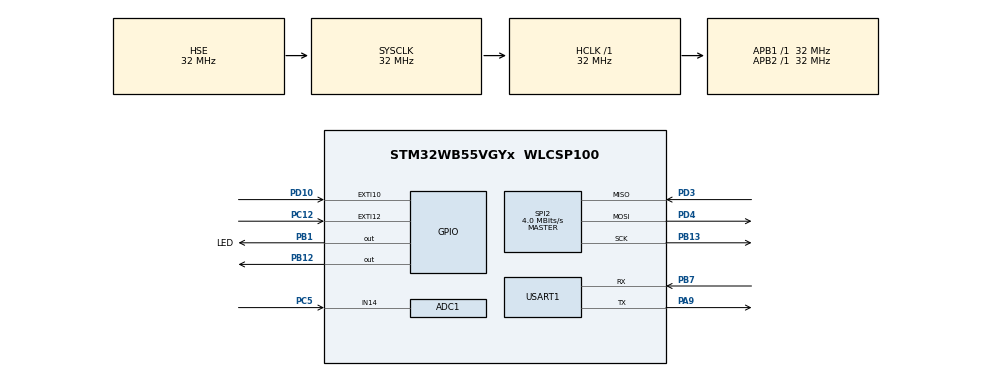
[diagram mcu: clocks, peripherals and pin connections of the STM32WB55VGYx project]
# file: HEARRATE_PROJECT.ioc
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ADC1.Channel-0\#ChannelRegularConversion=ADC_CHANNEL_14
ADC1.NbrOfConversionFlag=1
ADC1.OffsetNumber-0\#ChannelRegularConversion=ADC_OFFSET_NONE
ADC1.Rank-0\#ChannelRegularConversion=1
ADC1.SamplingTime-0\#ChannelRegularConversion=ADC_SAMPLETIME_2CYCLES_5
ADC1.master=1
Dma.Request0=USART1_RX
Dma.Request1=USART1_TX
Dma.Request2=SPI2_RX
Dma.Request3=SPI2_TX
Dma.SPI2_RX.2.Direction=DMA_PERIPH_TO_MEMORY
Dma.SPI2_RX.2.EventEnable=DISABLE
Dma.SPI2_RX.2.Instance=DMA1_Channel3
Dma.SPI2_RX.2.MemDataAlignment=DMA_MDATAALIGN_BYTE
Dma.SPI2_RX.2.MemInc=DMA_MINC_ENABLE
Dma.SPI2_RX.2.Mode=DMA_NORMAL
Dma.SPI2_RX.2.PeriphDataAlignment=DMA_PDATAALIGN_BYTE
Dma.SPI2_RX.2.PeriphInc=DMA_PINC_DISABLE
Dma.SPI2_RX.2.Polarity=HAL_DMAMUX_REQ_GEN_RISING
Dma.SPI2_RX.2.Priority=DMA_PRIORITY_LOW
Dma.SPI2_RX.2.RequestNumber=1
Dma.SPI2_RX.2.SignalID=NONE
Dma.SPI2_RX.2.SyncEnable=DISABLE
Dma.SPI2_RX.2.SyncPolarity=HAL_DMAMUX_SYNC_NO_EVENT
Dma.SPI2_RX.2.SyncRequestNumber=1
Dma.SPI2_RX.2.SyncSignalID=NONE
Dma.SPI2_TX.3.Direction=DMA_MEMORY_TO_PERIPH
Dma.SPI2_TX.3.EventEnable=DISABLE
Dma.SPI2_TX.3.Instance=DMA1_Channel4
Dma.SPI2_TX.3.MemDataAlignment=DMA_MDATAALIGN_BYTE
Dma.SPI2_TX.3.MemInc=DMA_MINC_ENABLE
Dma.SPI2_TX.3.Mode=DMA_NORMAL
Dma.SPI2_TX.3.PeriphDataAlignment=DMA_PDATAALIGN_BYTE
Dma.SPI2_TX.3.PeriphInc=DMA_PINC_DISABLE
Dma.SPI2_TX.3.Polarity=HAL_DMAMUX_REQ_GEN_RISING
Dma.SPI2_TX.3.Priority=DMA_PRIORITY_LOW
Dma.SPI2_TX.3.RequestNumber=1
Dma.SPI2_TX.3.SignalID=NONE
Dma.SPI2_TX.3.SyncEnable=DISABLE
Dma.SPI2_TX.3.SyncPolarity=HAL_DMAMUX_SYNC_NO_EVENT
Dma.SPI2_TX.3.SyncRequestNumber=1
Dma.SPI2_TX.3.SyncSignalID=NONE
Dma.USART1_RX.0.Direction=DMA_PERIPH_TO_MEMORY
Dma.USART1_RX.0.EventEnable=DISABLE
Dma.USART1_RX.0.Instance=DMA1_Channel1
Dma.USART1_RX.0.MemDataAlignment=DMA_MDATAALIGN_BYTE
Dma.USART1_RX.0.MemInc=DMA_MINC_ENABLE
Dma.USART1_RX.0.Mode=DMA_NORMAL
Dma.USART1_RX.0.PeriphDataAlignment=DMA_PDATAALIGN_BYTE
Dma.USART1_RX.0.PeriphInc=DMA_PINC_DISABLE
Dma.USART1_RX.0.Polarity=HAL_DMAMUX_REQ_GEN_RISING
Dma.USART1_RX.0.Priority=DMA_PRIORITY_LOW
Dma.USART1_RX.0.RequestNumber=1
Dma.USART1_RX.0.SignalID=NONE
Dma.USART1_RX.0.SyncEnable=DISABLE
Dma.USART1_RX.0.SyncPolarity=HAL_DMAMUX_SYNC_NO_EVENT
Dma.USART1_RX.0.SyncRequestNumber=1
Dma.USART1_RX.0.SyncSignalID=NONE
Dma.USART1_TX.1.Direction=DMA_MEMORY_TO_PERIPH
Dma.USART1_TX.1.EventEnable=DISABLE
Dma.USART1_TX.1.Instance=DMA1_Channel2
Dma.USART1_TX.1.MemDataAlignment=DMA_MDATAALIGN_BYTE
Dma.USART1_TX.1.MemInc=DMA_MINC_ENABLE
Dma.USART1_TX.1.Mode=DMA_NORMAL
Dma.USART1_TX.1.PeriphDataAlignment=DMA_PDATAALIGN_BYTE
Dma.USART1_TX.1.PeriphInc=DMA_PINC_DISABLE
Dma.USART1_TX.1.Polarity=HAL_DMAMUX_REQ_GEN_RISING
Dma.USART1_TX.1.Priority=DMA_PRIORITY_LOW
Dma.USART1_TX.1.RequestNumber=1
Dma.USART1_TX.1.SignalID=NONE
Dma.USART1_TX.1.SyncEnable=DISABLE
Dma.USART1_TX.1.SyncPolarity=HAL_DMAMUX_SYNC_NO_EVENT
Dma.USART1_TX.1.SyncRequestNumber=1
Dma.USART1_TX.1.SyncSignalID=NONE
Mcu.Family=STM32WB
Mcu.Name=STM32WB55VGYx
Mcu.Package=WLCSP100
NVIC.DMA1_Channel1_IRQn=true\:0\:0\:false\:false\:true\:false\:true\:true
NVIC.DMA1_Channel2_IRQn=true\:0\:0\:false\:false\:true\:false\:true\:true
NVIC.DMA1_Channel3_IRQn=true\:0\:0\:false\:false\:true\:false\:true\:true
NVIC.DMA1_Channel4_IRQn=true\:0\:0\:false\:false\:true\:false\:true\:true
NVIC.HSEM_IRQn=true\:0\:0\:false\:false\:true\:false\:true\:true
NVIC.PriorityGroup=NVIC_PRIORITYGROUP_4
NVIC.RTC_WKUP_IRQn=true\:0\:0\:false\:false\:true\:true\:true\:true
NVIC.SPI2_IRQn=true\:0\:0\:false\:false\:true\:true\:true\:true
NVIC.USART1_IRQn=true\:0\:0\:false\:false\:true\:true\:true\:true
OSC_IN.Mode=HSE-External-Oscillator
OSC_IN.Signal=RCC_OSC_IN
OSC_OUT.Mode=HSE-External-Oscillator
OSC_OUT.Signal=RCC_OSC_OUT
PA13.Mode=Serial_Wire
PA13.Signal=SYS_JTMS-SWDIO
PA14.Mode=Serial_Wire
PA14.Signal=SYS_JTCK-SWCLK
PA9.Mode=Asynchronous
PA9.Signal=USART1_TX
PB1.GPIO_Label=LED
PB1.Signal=GPIO_Output
PB12.Signal=GPIO_Output
PB13.Mode=Full_Duplex_Master
PB13.Signal=SPI2_SCK
PB7.Mode=Asynchronous
PB7.Signal=USART1_RX
PC12.Signal=GPXTI12
PC14-OSC32_IN.Mode=LSE-External-Oscillator
PC14-OSC32_IN.Signal=RCC_OSC32_IN
PC15-OSC32_OUT.Mode=LSE-External-Oscillator
PC15-OSC32_OUT.Signal=RCC_OSC32_OUT
PC5.Signal=ADCx_IN14
PD10.Signal=GPXTI10
PD3.Mode=Full_Duplex_Master
PD3.Signal=SPI2_MISO
PD4.Mode=Full_Duplex_Master
PD4.Signal=SPI2_MOSI
ProjectManager.HeapSize=0x200
ProjectManager.StackSize=0x400
ProjectManager.TargetToolchain=STM32CubeIDE
RCC.AHBFreq_Value=32000000
RCC.APB1Freq_Value=32000000
RCC.APB1TimFreq_Value=32000000
RCC.APB2Freq_Value=32000000
RCC.APB2TimFreq_Value=32000000
RCC.APB3Freq_Value=16000000
RCC.CortexFreq_Value=32000000
RCC.HCLKFreq_Value=32000000
RCC.HSE_VALUE=32000000
RCC.HSI48_VALUE=48000000
RCC.HSI_VALUE=16000000
RCC.RFWKPClockSelection=RCC_RFWKPCLKSOURCE_LSE
RCC.RTCClockSelection=RCC_RTCCLKSOURCE_LSE
RCC.SMPSCLockSelection=RCC_SMPSCLKSOURCE_HSE
RCC.SYSCLKFreq_VALUE=32000000
RCC.SYSCLKSource=RCC_SYSCLKSOURCE_HSE
RCC.VCOOutputFreq_Value=32000000
RF1.Mode=RF1_Activate
RF1.Signal=RF_RF1
SH.ADCx_IN14.0=ADC1_IN14,IN14-Single-Ended
SPI2.BaudRatePrescaler=SPI_BAUDRATEPRESCALER_8
SPI2.CLKPhase=SPI_PHASE_1EDGE
SPI2.CalculateBaudRate=4.0 MBits/s
SPI2.DataSize=SPI_DATASIZE_8BIT
SPI2.Direction=SPI_DIRECTION_2LINES
SPI2.Mode=SPI_MODE_MASTER
SPI2.VirtualType=VM_MASTER
STM32_WPAN.BLE_DBG_APP_EN=1
STM32_WPAN.BT_SIG_HEART_RATE_SENSOR=Disabled
STM32_WPAN.CFG_DEBUGGER_SUPPORTED=1
STM32_WPAN.CFG_DEBUG_APP_TRACE=1
STM32_WPAN.CFG_DEBUG_BLE_TRACE=1
STM32_WPAN.CFG_DEBUG_TRACE_FULL=1
STM32_WPAN.CFG_DEBUG_TRACE_LIGHT=0
STM32_WPAN.CFG_DEBUG_TRACE_UART=hw_uart1
STM32_WPAN.CFG_HW_USART1_ENABLED=1
STM32_WPAN.CFG_LPM_SUPPORTED=1
STM32_WPAN.CFG_LSCLK_LSE=0
STM32_WPAN.CFG_USE_SMPS=1
STM32_WPAN.CUSTOM_P2P_SERVER=Disabled
STM32_WPAN.CUSTOM_TEMPLATE=Enabled
STM32_WPAN.INCLUDE_AD_TYPE_COMPLETE_LOCAL_NAME=0
STM32_WPAN.INCLUDE_AD_TYPE_TX_POWER_LEVEL=1
STM32_WPAN.LOCAL_NAME=HEART
STM32_WPAN.LOCAL_NAME_FORMATTED=,'H','E','A','R','T'
STM32_WPAN.NUMBER_OF_SERVICES=1
STM32_WPAN.SERVICE1_CHAR1_ATTR_PERMISSION_AUTHEN_READ=\ 
STM32_WPAN.SERVICE1_CHAR1_ATTR_PERMISSION_AUTHEN_WRITE=\ 
STM32_WPAN.SERVICE1_CHAR1_ATTR_PERMISSION_AUTHOR_READ=\ 
STM32_WPAN.SERVICE1_CHAR1_ATTR_PERMISSION_AUTHOR_WRITE=\ 
STM32_WPAN.SERVICE1_CHAR1_GATT_NOTIFY_ATTRIBUTE_WRITE=\ 
STM32_WPAN.SERVICE1_CHAR1_GATT_NOTIFY_READ_REQ_AND_WAIT_FOR_APPL_RESP=\ 
STM32_WPAN.SERVICE1_CHAR1_GATT_NOTIFY_WRITE_REQ_AND_WAIT_FOR_APPL_RESP=\ 
STM32_WPAN.SERVICE1_CHAR1_LONG_NAME=DATA_SEND
STM32_WPAN.SERVICE1_CHAR1_PROP_NOTIFY=CHAR_PROP_NOTIFY
STM32_WPAN.SERVICE1_CHAR1_SHORT_NAME=DATA_SEND
STM32_WPAN.SERVICE1_LONG_NAME=PEDOMETER
STM32_WPAN.SERVICE1_SHORT_NAME=PEDOMETER
USART1.FIFOMode=FIFOMODE_DISABLE
USART1.VirtualMode-Asynchronous=VM_ASYNC
VP_HSEM_VS_HSEM.Mode=HSEM_Activate
VP_IPCC_VS_IPCC.Mode=IPCC_Activate
VP_MEMORYMAP_VS_MEMORYMAP.Mode=CurAppReg
VP_RTC_VS_RTC_Activate.Mode=RTC_Enabled
VP_RTC_VS_RTC_WakeUp_intern.Mode=WakeUp
VP_SEQUENCER_VS_SEQUENCER.Mode=SEQUENCER_Enabled
VP_STM32_WPAN_VS_BLE_HOST.Mode=STM32_WPAN_Enabled
VP_SYS_V_PVD_IN.Mode=Mode_PVD_Int
VP_TINY_LPM_VS_TINY_LPM.Mode=TINY_LPM_Enabled
board=custom

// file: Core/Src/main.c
/* USER CODE BEGIN Header */
/**
  ******************************************************************************
  * @file           : main.c
  * @brief          : Main program body
  ******************************************************************************
  * @attention
  *
  * Copyright (c) 2025 STMicroelectronics.
  * All rights reserved.
  *
  * This software is licensed under terms that can be found in the LICENSE file
  * in the root directory of this software component.
  * If no LICENSE file comes with this software, it is provided AS-IS.
  *
  ******************************************************************************
  */
/* USER CODE END Header */
#include "main.h"
#include "adc.h"
#include "dma.h"
#include "ipcc.h"
#include "memorymap.h"
#include "rf.h"
#include "rtc.h"
#include "spi.h"
#include "usart.h"
#include "gpio.h"

/* USER CODE BEGIN Includes */
#include "IMU.h"
#include"dbg_trace.h"
#include"Pedometer.h"
/* USER CODE END Includes */

void SystemClock_Config(void);
void PeriphCommonClock_Config(void);

int main(void)
{

  /* MCU Configuration--------------------------------------------------------*/

  /* Reset of all peripherals, Initializes the Flash interface and the Systick. */
  HAL_Init();
  /* Config code for STM32_WPAN (HSE Tuning must be done before system clock configuration) */
  MX_APPE_Config();

  /* Configure the system clock */
  SystemClock_Config();

  /* Configure the peripherals common clocks */
  PeriphCommonClock_Config();

  /* IPCC initialisation */
  MX_IPCC_Init();

  /* Initialize all configured peripherals */
  MX_RF_Init();
  MX_GPIO_Init();
  MX_DMA_Init();
  MX_ADC1_Init();
  MX_RTC_Init();
  MX_SPI2_Init();
  MX_USART1_UART_Init();
  /* USER CODE BEGIN 2 */
  HAL_GPIO_WritePin(LED_GPIO_Port, LED_Pin, GPIO_PIN_SET);
  APPD_Init();
//  lsm6dsv16b_pedometer();
  lsm6dsv16b_pedometer();

  /* USER CODE END 2 */

  /* Init code for STM32_WPAN */
  MX_APPE_Init();

  /* Infinite loop */
  while (1)
  {
    MX_APPE_Process();

  }
}

void SystemClock_Config(void)
{
  RCC_OscInitTypeDef RCC_OscInitStruct = {0};
  RCC_ClkInitTypeDef RCC_ClkInitStruct = {0};

  /** Macro to configure the PLL multiplication factor
  */
  __HAL_RCC_PLL_PLLM_CONFIG(RCC_PLLM_DIV1);

  /** Macro to configure the PLL clock source
  */
  __HAL_RCC_PLL_PLLSOURCE_CONFIG(RCC_PLLSOURCE_MSI);

  /** Configure LSE Drive Capability
  */
  HAL_PWR_EnableBkUpAccess();
  __HAL_RCC_LSEDRIVE_CONFIG(RCC_LSEDRIVE_MEDIUMHIGH);

  /** Configure the main internal regulator output voltage
  */
  __HAL_PWR_VOLTAGESCALING_CONFIG(PWR_REGULATOR_VOLTAGE_SCALE1);

  /** Initializes the RCC Oscillators according to the specified parameters
  * in the RCC_OscInitTypeDef structure.
  */
  RCC_OscInitStruct.OscillatorType = RCC_OSCILLATORTYPE_HSI|RCC_OSCILLATORTYPE_HSE
                              |RCC_OSCILLATORTYPE_LSE|RCC_OSCILLATORTYPE_MSI;
  RCC_OscInitStruct.HSEState = RCC_HSE_ON;
  RCC_OscInitStruct.LSEState = RCC_LSE_ON;
  RCC_OscInitStruct.HSIState = RCC_HSI_ON;
  RCC_OscInitStruct.MSIState = RCC_MSI_ON;
  RCC_OscInitStruct.HSICalibrationValue = RCC_HSICALIBRATION_DEFAULT;
  RCC_OscInitStruct.MSICalibrationValue = RCC_MSICALIBRATION_DEFAULT;
  RCC_OscInitStruct.MSIClockRange = RCC_MSIRANGE_6;
  RCC_OscInitStruct.PLL.PLLState = RCC_PLL_NONE;
  if (HAL_RCC_OscConfig(&RCC_OscInitStruct) != HAL_OK)
  {
    Error_Handler();
  }

  /** Configure the SYSCLKSource, HCLK, PCLK1 and PCLK2 clocks dividers
  */
  RCC_ClkInitStruct.ClockType = RCC_CLOCKTYPE_HCLK4|RCC_CLOCKTYPE_HCLK2
                              |RCC_CLOCKTYPE_HCLK|RCC_CLOCKTYPE_SYSCLK
                              |RCC_CLOCKTYPE_PCLK1|RCC_CLOCKTYPE_PCLK2;
  RCC_ClkInitStruct.SYSCLKSource = RCC_SYSCLKSOURCE_HSE;
  RCC_ClkInitStruct.AHBCLKDivider = RCC_SYSCLK_DIV1;
  RCC_ClkInitStruct.APB1CLKDivider = RCC_HCLK_DIV1;
  RCC_ClkInitStruct.APB2CLKDivider = RCC_HCLK_DIV1;
  RCC_ClkInitStruct.AHBCLK2Divider = RCC_SYSCLK_DIV1;
  RCC_ClkInitStruct.AHBCLK4Divider = RCC_SYSCLK_DIV1;

  if (HAL_RCC_ClockConfig(&RCC_ClkInitStruct, FLASH_LATENCY_1) != HAL_OK)
  {
    Error_Handler();
  }
}

void PeriphCommonClock_Config(void)
{
  RCC_PeriphCLKInitTypeDef PeriphClkInitStruct = {0};

  /** Initializes the peripherals clock
  */
  PeriphClkInitStruct.PeriphClockSelection = RCC_PERIPHCLK_SMPS|RCC_PERIPHCLK_RFWAKEUP;
  PeriphClkInitStruct.RFWakeUpClockSelection = RCC_RFWKPCLKSOURCE_LSE;
  PeriphClkInitStruct.SmpsClockSelection = RCC_SMPSCLKSOURCE_HSE;
  PeriphClkInitStruct.SmpsDivSelection = RCC_SMPSCLKDIV_RANGE0;

  if (HAL_RCCEx_PeriphCLKConfig(&PeriphClkInitStruct) != HAL_OK)
  {
    Error_Handler();
  }
}

void Error_Handler(void)
{
  __disable_irq();
  while (1)
  {
  }
}
